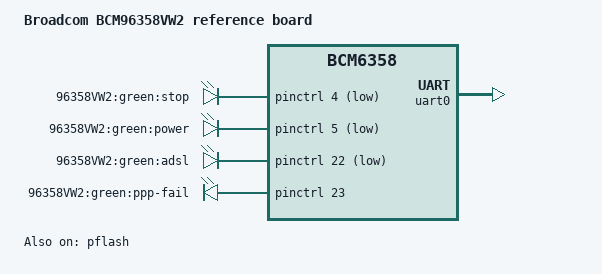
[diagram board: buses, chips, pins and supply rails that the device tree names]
/dts-v1/;

#include "bcm6358.dtsi"

#include <dt-bindings/input/input.h>

/ {
	model = "Broadcom BCM96358VW2 reference board";
	compatible = "brcm,bcm96358vw2", "brcm,bcm6358";

	chosen {
		bootargs = "root=/dev/mtdblock2 rootfstype=squashfs,jffs2 noinitrd console=ttyS0,115200";
		stdout-path = "serial0:115200n8";
	};

	gpio-leds {
		compatible = "gpio-leds";

		stop_green {
			label = "96358VW2:green:stop";
			gpios = <&pinctrl 4 1>;
		};
		power_green {
			label = "96358VW2:green:power";
			gpios = <&pinctrl 5 1>;
			default-state = "on";
		};
		adsl_green {
			label = "96358VW2:green:adsl";
			gpios = <&pinctrl 22 1>;
		};
		ppp_fail_green {
			label = "96358VW2:green:ppp-fail";
			gpios = <&pinctrl 23 0>;
		};
	};
};

&pflash {
	status = "ok";

	linux,part-probe = "bcm63xxpart";
};

&uart0 {
	status = "ok";
};
